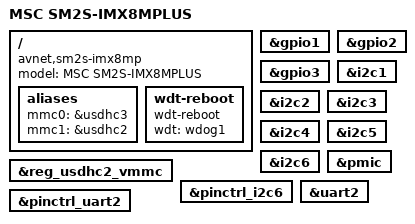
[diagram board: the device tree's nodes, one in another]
// SPDX-License-Identifier: GPL-2.0+
/*
 * Copyright 2019 NXP
 */

#include "imx8mp-u-boot.dtsi"

/ {
	model = "MSC SM2S-IMX8MPLUS";
	compatible = "avnet,sm2s-imx8mp", "fsl,imx8mp";

	aliases {
		mmc0 = &usdhc3;
		mmc1 = &usdhc2;
	};

	wdt-reboot {
		compatible = "wdt-reboot";
		wdt = <&wdog1>;
		bootph-pre-ram;
	};
};

&reg_usdhc2_vmmc {
	bootph-pre-ram;
};

&gpio1 {
	bootph-pre-ram;
};

&gpio2 {
	bootph-pre-ram;
};

&gpio3 {
	bootph-pre-ram;
};

&i2c1 {
	bootph-pre-ram;
};

&i2c2 {
	bootph-pre-ram;
};

&i2c3 {
	bootph-pre-ram;
};

&i2c4 {
	bootph-pre-ram;
};

&i2c5 {
	bootph-pre-ram;
};

&i2c6 {
	bootph-pre-ram;
};

&pinctrl_i2c6 {
	bootph-pre-ram;
};

&pmic {
	bootph-pre-ram;
};

&uart2 {
	bootph-pre-ram;
};

&pinctrl_uart2 {
	bootph-pre-ram;
};
